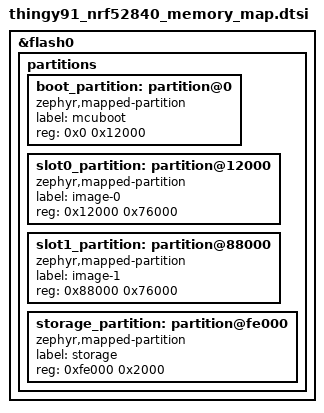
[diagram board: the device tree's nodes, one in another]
/*
 * Copyright (c) 2026 Nordic Semiconductor ASA
 *
 * SPDX-License-Identifier: LicenseRef-Nordic-5-Clause
 */

&flash0 {
	/delete-node/ partitions;

	partitions {
		#address-cells = <1>;
		#size-cells = <1>;
		ranges;

		boot_partition: partition@0 {
			compatible = "zephyr,mapped-partition";
			label = "mcuboot";
			reg = <0x0 0x12000>;
		};

		slot0_partition: partition@12000 {
			compatible = "zephyr,mapped-partition";
			label = "image-0";
			reg = <0x12000 0x76000>;
		};

		slot1_partition: partition@88000 {
			compatible = "zephyr,mapped-partition";
			label = "image-1";
			reg = <0x88000 0x76000>;
		};

		storage_partition: partition@fe000 {
			compatible = "zephyr,mapped-partition";
			label = "storage";
			reg = <0xfe000 0x2000>;
		};
	};
};
